# f28003x_hic_cfg_regs register map
Vendor: Texas Instruments
Peripheral module from a debugger description file (folder C2000).
Address unit: 16 bits
Registers are 32-bit, read-write, no defined reset value unless marked. A register's access mark holds for its fields unless they carry their own. Offsets are as the file gives them; lines under a group give offsets from that group; [hi:lo] are bit positions; {n}, {i} and the like mark numbered series; 'fields as' and 'values as' point back to an identical list; <NAME> marks a mode.

## HIC_CFG_REGS — HIC CFG Registers
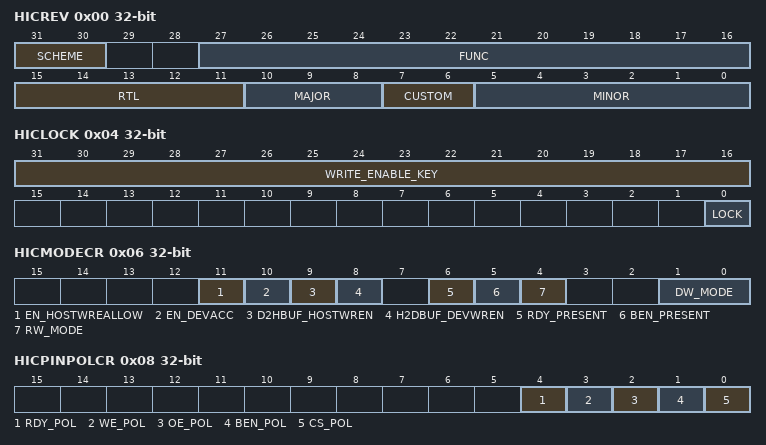
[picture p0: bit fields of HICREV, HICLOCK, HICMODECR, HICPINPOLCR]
0x00 HICREV ro — Module Revision Register
  [31:30] SCHEME — Defines Scheme for Module
  [27:16] FUNC — Functional Release Number
  [15:11] RTL — Design Release Number
  [10:8] MAJOR — Major Revision Number
  [7:6] CUSTOM — Custom Module Number
  [5:0] MINOR — Minor Revision Number
0x02 HICGCR — Global Control Register
  [3:0] HICEN — Host Interface Enable
0x04 HICLOCK — Lock Register
  [31:16] WRITE_ENABLE_KEY — Key for enabling write
  [0] LOCK — LOCK enable
0x06 HICMODECR — Mode Control Register
  [11] EN_HOSTWREALLOW — Enable Host Write to EALLOWCTL register
  [10] EN_DEVACC — Enable Host access to Device region
  [9] D2HBUF_HOSTWREN — Write Enable for Host to D2H Buffer
  [8] H2DBUF_DEVWREN — Write Enable for Device to H2D Buffer
  [6] RDY_PRESENT — Ready pin present
  [5] BEN_PRESENT — Byte Enable Pins are present
  [4] RW_MODE — Read-Write Mode
  [1:0] DW_MODE — Data Width Mode
0x08 HICPINPOLCR — Pin Polarity Control Register
  [4] RDY_POL — Ready Polarity
  [3] WE_POL — Write Enable Polarity
  [2] OE_POL — Output Enable Polarity
  [1] BEN_POL — Byte Enable Polarity
  [0] CS_POL — Chip Select Polarity
0x0A HICBASESEL — Base Select Register
  [2:0] BASE_SELECT
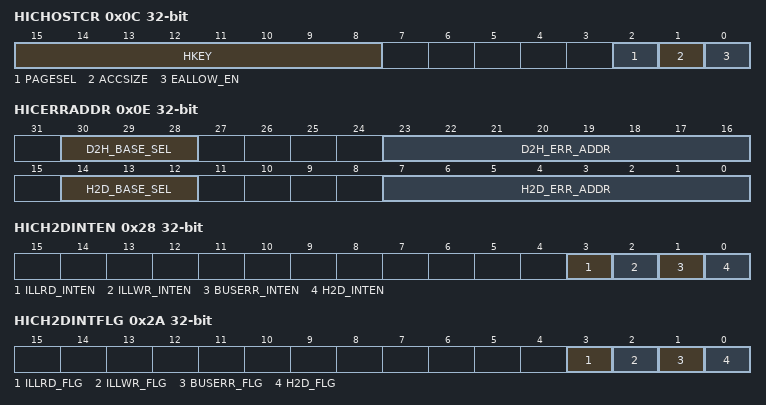
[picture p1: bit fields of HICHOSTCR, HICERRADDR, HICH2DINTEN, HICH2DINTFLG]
0x0C HICHOSTCR — HIC Host Control Register
  [15:8] HKEY — Host Key
  [2] PAGESEL — Page Select
  [1] ACCSIZE — Access Size
  [0] EALLOW_EN — EALLOW Enable
0x0E HICERRADDR ro — Host Error Address register
  [30:28] D2H_BASE_SEL — Base Select corresponding to D2H error event
  [23:16] D2H_ERR_ADDR — Address of the Host bus captured upon an error for Host
  [14:12] H2D_BASE_SEL — Base Select corresponding to H2D error event
  [7:0] H2D_ERR_ADDR — Address of the Host bus captured upon an error for Device
0x10 HICH2DTOKEN — Host to Device Token Register
  [31:0] H2D_TOKEN — Host to Device Token
0x12 HICD2HTOKEN — Devie to Host Token Register
  [31:0] D2H_TOKEN — Device To Host Token
{0x14+2i} HICDBADDR{i} (i=0..7) — Device Base Address Register {i}
  [31:7] BASE_ADDR — Base address of device region
0x28 HICH2DINTEN — H2D Interrupt Enable
  [3] ILLRD_INTEN — Illegal Read event interrupt enable
  [2] ILLWR_INTEN — Illegal Write event interrupt enable
  [1] BUSERR_INTEN — BusError Interrupt Enable
  [0] H2D_INTEN — Host To Device Interrupt Enable
0x2A HICH2DINTFLG ro — H2D Interrupt status Flag
  [3] ILLRD_FLG — Illegal read event interrupt flag
  [2] ILLWR_FLG — Illegal write event interrupt flag
  [1] BUSERR_FLG — BusError Interrupt Flag
  [0] H2D_FLG — Host To Device Interrupt Flag
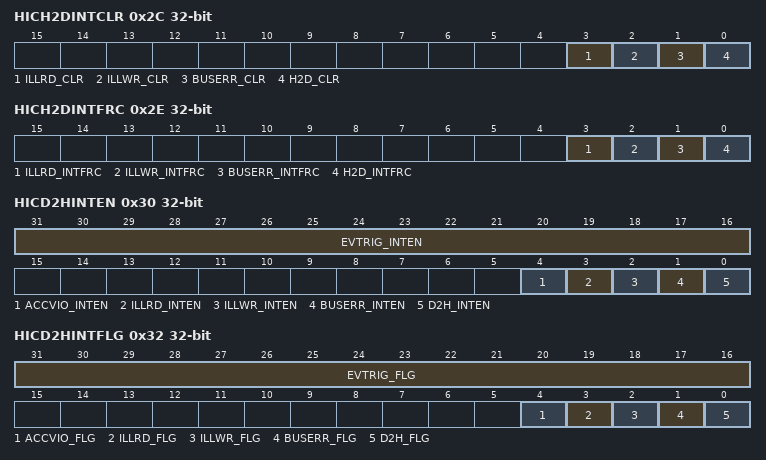
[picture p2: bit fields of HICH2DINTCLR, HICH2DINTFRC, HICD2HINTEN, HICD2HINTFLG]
0x2C HICH2DINTCLR — H2D Interrupt status Clear
  [3] ILLRD_CLR — Illegal Read Interrupt Clear
  [2] ILLWR_CLR — Illegal Write Interrupt Clear
  [1] BUSERR_CLR — BusError Interrupt Clear
  [0] H2D_CLR — Host To Device Interrupt Clear
0x2E HICH2DINTFRC — H2D Interrupt Set Force
  [3] ILLRD_INTFRC — Illegal Read Interrupt Force Set
  [2] ILLWR_INTFRC — Illegal Write Interrupt Force Set
  [1] BUSERR_INTFRC — BusError Interrupt Force Set
  [0] H2D_INTFRC — Host To Device Force Set
0x30 HICD2HINTEN — D2H Interrupt Enable
  [31:16] EVTRIG_INTEN — Event Trigger Interrupt Enable
  [4] ACCVIO_INTEN — Access Violation Interrupt Enable
  [3] ILLRD_INTEN — Illegal Read event Interrupt Enable
  [2] ILLWR_INTEN — Illegal Write event Interrupt Enable
  [1] BUSERR_INTEN — BusError Interrupt Enable
  [0] D2H_INTEN — Device to Host Data Ready Interrupt Enable
0x32 HICD2HINTFLG ro — D2H Interrupt status Flag
  [31:16] EVTRIG_FLG — Event Trigger Flag
  [4] ACCVIO_FLG — Access Violation Flag
  [3] ILLRD_FLG — Illegal Read event Flag
  [2] ILLWR_FLG — Illegal Write event Flag
  [1] BUSERR_FLG — BusError Flag
  [0] D2H_FLG — Device to Host Data Ready Flag
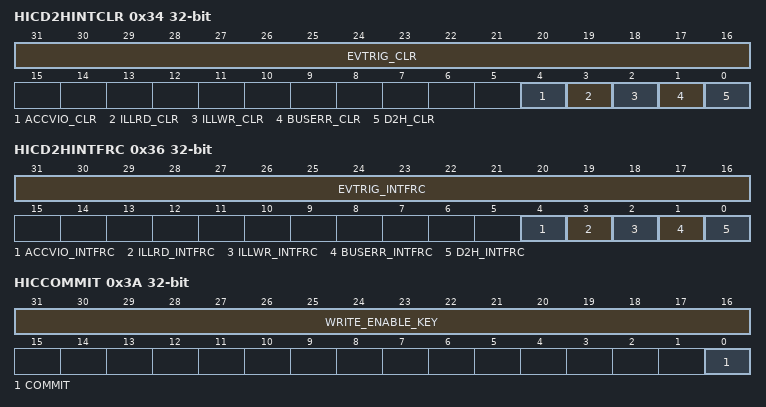
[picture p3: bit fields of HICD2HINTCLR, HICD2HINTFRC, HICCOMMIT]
0x34 HICD2HINTCLR — D2H Interrupt status Clear
  [31:16] EVTRIG_CLR — Event Trigger Interrupt Clear
  [4] ACCVIO_CLR — Access Violation Interrupt Clear
  [3] ILLRD_CLR — Illegal Read Interrupt Clear
  [2] ILLWR_CLR — Illegal Write Interrupt Clear
  [1] BUSERR_CLR — BusError Interrupt Clear
  [0] D2H_CLR — Device to Host Interrupt Clear
0x36 HICD2HINTFRC — D2H Interrupt Set Force
  [31:16] EVTRIG_INTFRC — Event Trigger Interrupt Force Set
  [4] ACCVIO_INTFRC — Access Violation Interrupt Force Set
  [3] ILLRD_INTFRC — Illegal Read Interrupt Force Set
  [2] ILLWR_INTFRC — Illegal Write Interrupt Force Set
  [1] BUSERR_INTFRC — BusError Interrupt Force Set
  [0] D2H_INTFRC — Device to Host Force Set
0x38 HICACCVIOADDR ro — Access Violation Address
  [31:0] ACCVIO_ADDR — Address of the Initiator Port upon access violations
0x3A HICCOMMIT — Commit Register
  [31:16] WRITE_ENABLE_KEY — Key for enabling write
  [0] COMMIT — Commit bit for the HICLOCK register
{0x40+2i} H2D_BUF{i} (i=0..15) — Host to Device Buffer {i}
  [31:0] Data — Host to Device data buffer 0
{0x60+2i} D2H_BUF{i} (i=0..15) — Device to Host Buffer {i}
  [31:0] Data — Device to Host data buffer 0
